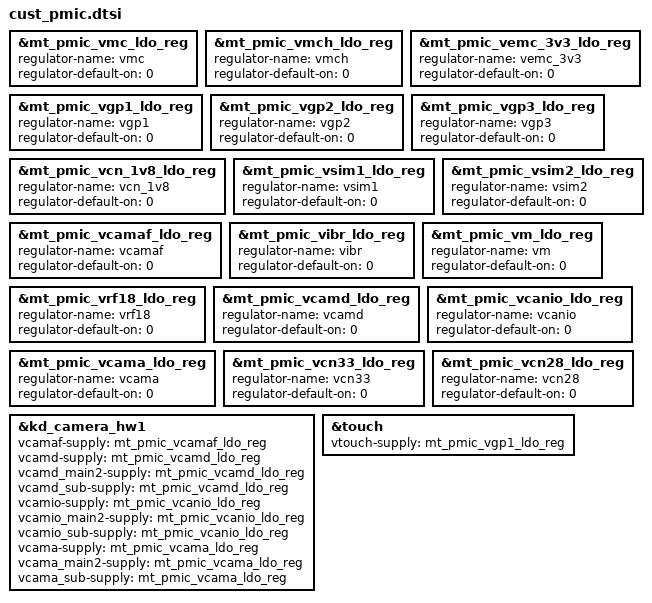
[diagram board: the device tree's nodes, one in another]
/*
 * Generated by MTK SP Drv_CodeGen Version 03.13.6	for MT6580. Copyright MediaTek Inc. (C) 2013.
 * Mon Apr  1 18:24:47 2019
 * Do Not Modify the File.
 */

/*************************
 * PMIC DTSI File
*************************/

&mt_pmic_vmc_ldo_reg {
	regulator-name = "vmc";
	regulator-default-on = <0>; /* 0:skip, 1: off, 2:on */
	status = "okay";
};
&mt_pmic_vmch_ldo_reg {
	regulator-name = "vmch";
	regulator-default-on = <0>; /* 0:skip, 1: off, 2:on */
	status = "okay";
};
&mt_pmic_vemc_3v3_ldo_reg {
	regulator-name = "vemc_3v3";
	regulator-default-on = <0>; /* 0:skip, 1: off, 2:on */
	status = "okay";
};
&mt_pmic_vgp1_ldo_reg {
	regulator-name = "vgp1";
	regulator-default-on = <0>; /* 0:skip, 1: off, 2:on */
	status = "okay";
};
&mt_pmic_vgp2_ldo_reg {
	regulator-name = "vgp2";
	regulator-default-on = <0>; /* 0:skip, 1: off, 2:on */
	status = "okay";
};
&mt_pmic_vgp3_ldo_reg {
	regulator-name = "vgp3";
	regulator-default-on = <0>; /* 0:skip, 1: off, 2:on */
	status = "okay";
};
&mt_pmic_vcn_1v8_ldo_reg {
	regulator-name = "vcn_1v8";
	regulator-default-on = <0>; /* 0:skip, 1: off, 2:on */
	status = "okay";
};
&mt_pmic_vsim1_ldo_reg {
	regulator-name = "vsim1";
	regulator-default-on = <0>; /* 0:skip, 1: off, 2:on */
	status = "okay";
};
&mt_pmic_vsim2_ldo_reg {
	regulator-name = "vsim2";
	regulator-default-on = <0>; /* 0:skip, 1: off, 2:on */
	status = "okay";
};
&mt_pmic_vcamaf_ldo_reg {
	regulator-name = "vcamaf";
	regulator-default-on = <0>; /* 0:skip, 1: off, 2:on */
	status = "okay";
};
&mt_pmic_vibr_ldo_reg {
	regulator-name = "vibr";
	regulator-default-on = <0>; /* 0:skip, 1: off, 2:on */
	status = "okay";
};
&mt_pmic_vm_ldo_reg {
	regulator-name = "vm";
	regulator-default-on = <0>; /* 0:skip, 1: off, 2:on */
	status = "okay";
};
&mt_pmic_vrf18_ldo_reg {
	regulator-name = "vrf18";
	regulator-default-on = <0>; /* 0:skip, 1: off, 2:on */
	status = "okay";
};
&mt_pmic_vcamd_ldo_reg {
	regulator-name = "vcamd";
	regulator-default-on = <0>; /* 0:skip, 1: off, 2:on */
	status = "okay";
};
&mt_pmic_vcanio_ldo_reg {
	regulator-name = "vcanio";
	regulator-default-on = <0>; /* 0:skip, 1: off, 2:on */
	status = "okay";
};
&mt_pmic_vcama_ldo_reg {
	regulator-name = "vcama";
	regulator-default-on = <0>; /* 0:skip, 1: off, 2:on */
	status = "okay";
};
&mt_pmic_vcn33_ldo_reg {
	regulator-name = "vcn33";
	regulator-default-on = <0>; /* 0:skip, 1: off, 2:on */
	status = "okay";
};
&mt_pmic_vcn28_ldo_reg {
	regulator-name = "vcn28";
	regulator-default-on = <0>; /* 0:skip, 1: off, 2:on */
	status = "okay";
};

&kd_camera_hw1 {
	vcamaf-supply = <&mt_pmic_vcamaf_ldo_reg>;

	vcamd-supply = <&mt_pmic_vcamd_ldo_reg>;
	vcamd_main2-supply = <&mt_pmic_vcamd_ldo_reg>;
	vcamd_sub-supply = <&mt_pmic_vcamd_ldo_reg>;

	vcamio-supply = <&mt_pmic_vcanio_ldo_reg>;
	vcamio_main2-supply = <&mt_pmic_vcanio_ldo_reg>;
	vcamio_sub-supply = <&mt_pmic_vcanio_ldo_reg>;

	vcama-supply = <&mt_pmic_vcama_ldo_reg>;
	vcama_main2-supply = <&mt_pmic_vcama_ldo_reg>;
	vcama_sub-supply = <&mt_pmic_vcama_ldo_reg>;

	status = "okay";
};

&touch {
	vtouch-supply = <&mt_pmic_vgp1_ldo_reg>;
	status = "okay";
};
